# wsoc_common_secure register map
Vendor: Texas Instruments
Peripheral module from a debugger description file (folder CC35X1E).
Registers are 32-bit, access per field, reset 0x0 unless marked. A register's access mark holds for its fields unless they carry their own. Offsets are as the file gives them; lines under a group give offsets from that group; [hi:lo] are bit positions; {n}, {i} and the like mark numbered series; 'fields as' and 'values as' point back to an identical list; <NAME> marks a mode.

## wsoc_common_secure
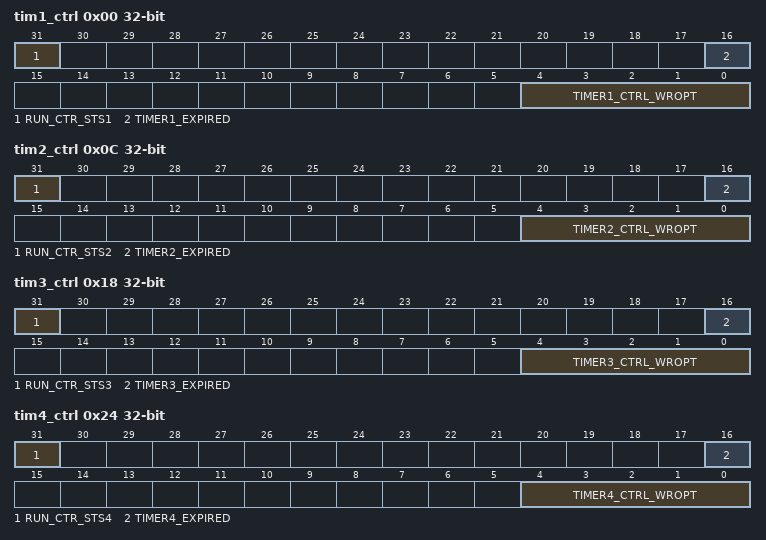
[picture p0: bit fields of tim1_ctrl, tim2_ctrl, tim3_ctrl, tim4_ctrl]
0x00 tim1_ctrl reset not defined — Control Timer Register1 (TIM1_CTRL)
  [31] RUN_CTR_STS1 ro — when value is 1, counter is running. the signal is asserted during load and count stages of the counter. if the counter is paused, this indication stays high and the pause bit should be checked as well.
  [16] TIMER1_EXPIRED ro — when set, timer has completed its count and asserted an interrupt. deasserted when started
  [4:0] TIMER1_CTRL_WROPT rw — Controls starting of timers and continuous or single shot modes; bit 3 = timer stop strobe. self-clearing. If timer running. setting bit stops the timer. A subsequent start will start the timer from load value; bit 2 = pause timer if set. Timer will stop counting down until cleared.; bit 1 = indicates continuous timer if set. single event if cleared; bit 0 = timer start. self-clearing;If stopped. setting bit 0 starts the timer. If running. setting bit 0 is ignores. bit 4 = when set, counter counts on clock freq (40MHz). when cleared, couter counts at usec frequency
0x04 tim1_load rw — Load Timer Register1 (TIM1_LOAD)
  [31:0] MEM_TIMER1_LOAD — Initial value for the timer to start counting
0x08 tim1_cnt ro — Value Timer Register1(TIM1_CNT)
  [31:0] TIMER1_COUNT — Represents the current value of the timer.
0x0C tim2_ctrl reset not defined — Control Timer Register2 (TIM2_CTRL)
  [31] RUN_CTR_STS2 ro — when value is 1, counter is running. the signal is asserted during load and count stages of the counter. if the counter is paused, this indication stays high and the pause bit should be checked as well.
  [16] TIMER2_EXPIRED ro — when set, timer has completed its count and asserted an interrupt. deasserted when started
  [4:0] TIMER2_CTRL_WROPT rw — Controls starting of timers and continuous or single shot modes; bit 3 = timer stop strobe. self-clearing. If timer running. setting bit stops the timer. A subsequent start will start the timer from load value; bit 2 = pause timer if set. Timer will stop counting down until cleared.; bit 1 = indicates continuous timer if set. single event if cleared; bit 0 = timer start. self-clearing;If stopped. setting bit 0 starts the timer. If running. setting bit 0 nored. bit 4 = when set, counter counts on clock freq (40MHz). when cleared, couter counts at usec frequency
0x10 tim2_load rw reset not defined — Load Timer Register2(TIM2_LOAD)
  [31:0] MEM_TIMER2_LOAD — Initial value for the timer to start counting
0x14 tim2_cnt ro — Value Timer Register2 (TIM2_CNT)
  [31:0] TIMER2_COUNT — Represents the current value of the timer.
0x18 tim3_ctrl — Control Timer Register3 (TIM3_CTRL)
  [31] RUN_CTR_STS3 ro — when value is 1, counter is running. the signal is asserted during load and count stages of the counter. if the counter is paused, this indication stays high and the pause bit should be checked as well.
  [16] TIMER3_EXPIRED ro — when set, timer has completed its count and asserted an interrupt. deasserted when started
  [4:0] TIMER3_CTRL_WROPT rw — Controls starting of timers and continuous or single shot modes; bit 3 = timer stop strobe. self-clearing. If timer running. setting bit stops the timer. A subsequent start will start the timer from load value; bit 2 = pause timer if set. Timer will stop counting down until cleared.; bit 1 = indicates continuous timer if set. single event if cleared; bit 0 = timer start. self-clearing;If stopped. setting bit 0 starts the timer. If running. setting bit 0 stops the timer. bit 4 = when set, counter counts on clock freq (40MHz). when cleared, couter counts at usec frequency
0x1C tim3_load rw — Load Timer Register3 (TIM3_LOAD)
  [31:0] MEM_TIMER3_LOAD — Initial value for the timer to start counting.min val is 5. actual count is 3-4 less then value
0x20 tim3_cnt ro — Value Timer Register3 (TIM3_CNT)
  [31:0] TIMER3_COUNT — Represents the current value of the timer.
0x24 tim4_ctrl — Control Timer Register4 (TIM4_CTRL)
  [31] RUN_CTR_STS4 ro — when value is 1, counter is running. the signal is asserted during load and count stages of the counter. if the counter is paused, this indication stays high and the pause bit should be checked as well.
  [16] TIMER4_EXPIRED ro — when set, timer has completed its count and asserted an interrupt. deasserted when started
  [4:0] TIMER4_CTRL_WROPT rw — Controls starting of timers and continuous or single shot modes; bit 3 = timer stop strobe. self-clearing. If timer running. setting bit stops the timer. A subsequent start will start the timer from load value; bit 2 = pause timer if set. Timer will stop counting down until cleared.; bit 1 = indicates continuous timer if set. single event if cleared; bit 0 = timer start. self-clearing;If stopped. setting bit 0 starts the timer. If running. setting bit 0 stops the timer. bit 4 = when set, counter counts on clock freq (40MHz). when cleared, couter counts at usec frequency
0x28 tim4_load rw — Load Timer Register4 (TIM4_LOAD)
  [31:0] MEM_TIMER4_LOAD — Initial value for the timer to start counting.min val is 5. actual count is 3-4 less then value
0x2C tim4_cnt ro — Value Timer Register4 (TIM4_CNT)
  [31:0] TIMER4_COUNT — Represents the current value of the timer.
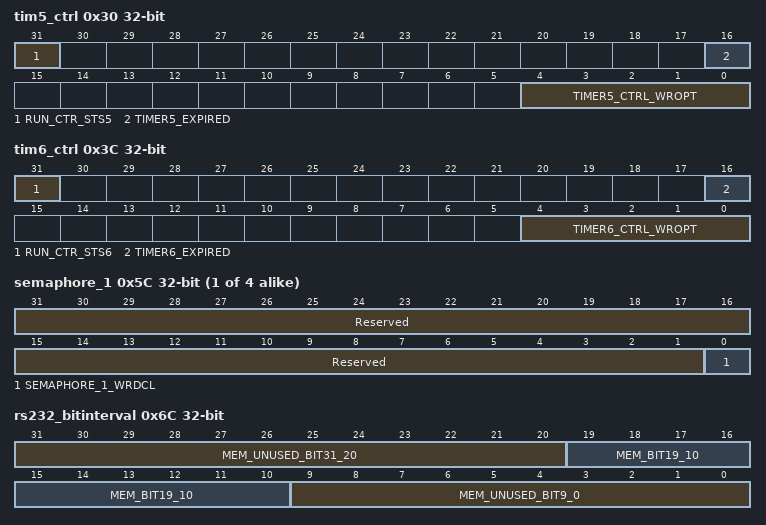
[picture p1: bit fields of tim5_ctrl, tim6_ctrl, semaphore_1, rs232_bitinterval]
0x30 tim5_ctrl — Control Timer Register5 (TIM5_CTRL)
  [31] RUN_CTR_STS5 ro — when value is 1, counter is running. the signal is asserted during load and count stages of the counter. if the counter is paused, this indication stays high and the pause bit should be checked as well.
  [16] TIMER5_EXPIRED ro — when set, timer has completed its count and asserted an interrupt. deasserted when started
  [4:0] TIMER5_CTRL_WROPT rw — Controls starting of timers and continuous or single shot modes; bit 3 = timer stop strobe. self-clearing. If timer running. setting bit stops the timer. A subsequent start will start the timer from load value; bit 2 = pause timer if set. Timer will stop counting down until cleared.; bit 1 = indicates continuous timer if set. single event if cleared; bit 0 = timer start. self-clearing;If stopped. setting bit 0 starts the timer. If running. setting bit 0 stops the timer. bit 4 = when set, counter counts on clock freq (40MHz). when cleared, couter counts at usec frequency
0x34 tim5_cnt ro — Value Timer Register5 (TIM5_CNT)
  [31:0] TIMER5_COUNT — Represents the current value of the timer.
0x38 tim5_load rw — Load Timer Register5 (TIM5_LOAD)
  [31:0] MEM_TIMER5_LOAD — Initial value for the timer to start counting. min val is 5. actual count is 3-4 less then value
0x3C tim6_ctrl — Control Timer Register6 (TIM6_CTRL)
  [31] RUN_CTR_STS6 ro — when value is 1, counter is running. the signal is asserted during load and count stages of the counter. if the counter is paused, this indication stays high and the pause bit should be checked as well.
  [16] TIMER6_EXPIRED ro — when set, timer has completed its count and asserted an interrupt. deasserted when started
  [4:0] TIMER6_CTRL_WROPT rw — Controls starting of timers and continuous or single shot modes; bit 3 = timer stop strobe. self-clearing. If timer running. setting bit stops the timer. A subsequent start will start the timer from load value; bit 2 = pause timer if set. Timer will stop counting down until cleared.; bit 1 = indicates continuous timer if set. single event if cleared; bit 0 = timer start. self-clearing;If stopped. setting bit 0 starts the timer. If running. setting bit 0 stops the timer. bit 4 = when set, counter counts on clock freq (40MHz). when cleared, couter counts at usec frequency
0x40 tim6_cnt ro — Value Timer Register6 (TIM6_CNT)
  [31:0] TIMER6_COUNT — Represents the current value of the timer.
0x44 tim6_load rw — Load Timer Register6 (TIM6_LOAD)
  [31:0] MEM_TIMER6_LOAD — Initial value for the timer to start counting. min val is 5. actual count is 3-4 less then value
0x48 wsoc_base_addresses reset not defined — base addresses for packet RAM. this is used by different modules. does not influence the OCP decoding itself
  [2:0] MEM_PRAM_BASE_ADDR rw — 3 msb (bits 23:21) of the PRAM base address
0x4C secga_skt_jump_tbl_base reset not defined
  [23:2] MEM_SKT_JUMP_TBL_ADDR rw — Nab Soket Jump table address. Each Table entry contain a 4B pointer to related socket DB entry. the value of this register is locked upon MEM_HIF_STATUS_LOCK @Init. In BSD_BYPASS Mode, when nab serves SDIO, only socket 0 DB exists in table. the rest 124B were increased to 124W are used to hold the Tx info table that is returned to the SDIO host at the end of each rcv() request. In the BSD_BYPASS Mode there is a restriction on value that can be set: MUST BE 128W aligned! since 2 lsb's are always 0 it means that MMR Fiels 7 LSBs MEM_SKT_JUMP_TBL_ADDR[6:0] should be set as 0
0x50 lnk_jump_tbl_base reset not defined
  [23:2] MEM_LNK_JUMP_TBL_ADDR rw
0x54 role_jump_tbl_base reset not defined
  [23:2] MEM_ROLE_JUMP_TBL_ADDR rw
0x58 secga_sub_desc_ram_base reset not defined
  [23:2] MEM_SUD_RAM_STS2_ADDR rw — Nab Sub descriptor RAM Base address. the value of this register is locked upon MEM_HIF_STATUS_LOCK @Init. In BSD_BYPASS Mode, when nab doesn't use the sud RAM, this register contains an MMR address. This MMR, plus pre-defined number of successive MMR's, return to the SDIO host as status information (a.k.a. Status 2) at the end of each rcv() request. In the BSD_BYPASS Mode there is a restriction on value that can be set: MUST BE 16W aligned! since 2 lsb's are always 0 it means that MMR Fiels 4 LSBs MEM_SUD_RAM_STS2_ADDR[3:0] should be set as 0
{0x58+4i} semaphore_{i} (i=1..4)
  [31:1] Reserved ro — rserved
  [0] SEMAPHORE_{i}_WRDCL rw — Set by read, cleared by write
0x6C rs232_bitinterval rw reset not defined — RS232 Bit Interval (RS232_BITINTERVAL) Register
  [31:20] MEM_UNUSED_BIT31_20
  [19:10] MEM_BIT19_10 — Bit Interval Value for sampling RS232 serial Data when the MAC Subsystem is working at 40 Mhz
  [9:0] MEM_UNUSED_BIT9_0
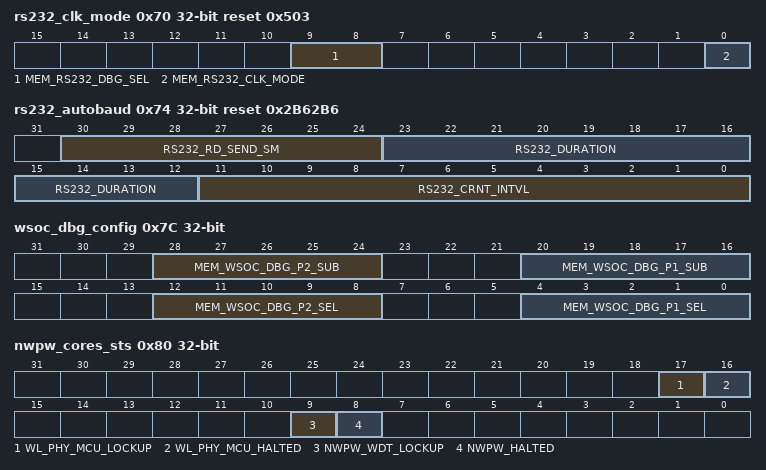
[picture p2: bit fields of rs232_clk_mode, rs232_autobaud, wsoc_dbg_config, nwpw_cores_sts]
0x70 rs232_clk_mode reset 0x503 — RS232 Clock Mode (RS232_CLK_MODE) Register
  [9:8] MEM_RS232_DBG_SEL rw — debug port select. 0 - default 0 1 - ocp debug port 2 - FSM debug port
  [0] MEM_RS232_CLK_MODE rw — RS232 Auto baud selection;0: RS232 calculates bit interval automatically based on the sleep clock frequency.;1: RS232 uses bit interval programmed by eCPU
0x74 rs232_autobaud ro reset 0x2B62B6 (reset mask 0xFFFFFF) — RS232 Auto Baud (RS232_AUTOBAUD) Register
  [30:24] RS232_RD_SEND_SM
  [23:12] RS232_DURATION — Number of ocp clocks measured in one sleep clock frequency
  [11:0] RS232_CRNT_INTVL — Current RS232 bit interval being used.
0x78 rs232_16_bit_slv — RS232 SLAVE Configuration
  [0] MEM_RS232_16_BIT_SLAVE rw — 0 = rs232 access 32 bit data slave 1 = rs232 access 16 bit data slave
0x7C wsoc_dbg_config — WSOC OCLA Debug Port Config register
  [28:24] MEM_WSOC_DBG_P2_SUB rw — Test Port Select (sub module = coulmn in XSL)
  [20:16] MEM_WSOC_DBG_P1_SUB rw — Test Port Select (sub module = coulmn in XSL)
  [12:8] MEM_WSOC_DBG_P2_SEL rw — Test Port module Select (up to 8 modules. bit 4 serves as test port selection)
  [4:0] MEM_WSOC_DBG_P1_SEL rw — Test Port module Select (up to 8 modules. bit 4 serves as test port selection)
0x80 nwpw_cores_sts ro
  [17] WL_PHY_MCU_LOCKUP — wl_phy_mcu lockup status
  [16] WL_PHY_MCU_HALTED — wl_phy_mcu halt status
  [9] NWPW_WDT_LOCKUP — wsoc_mcu lockup status
  [8] NWPW_HALTED — wsoc_mcu halt status
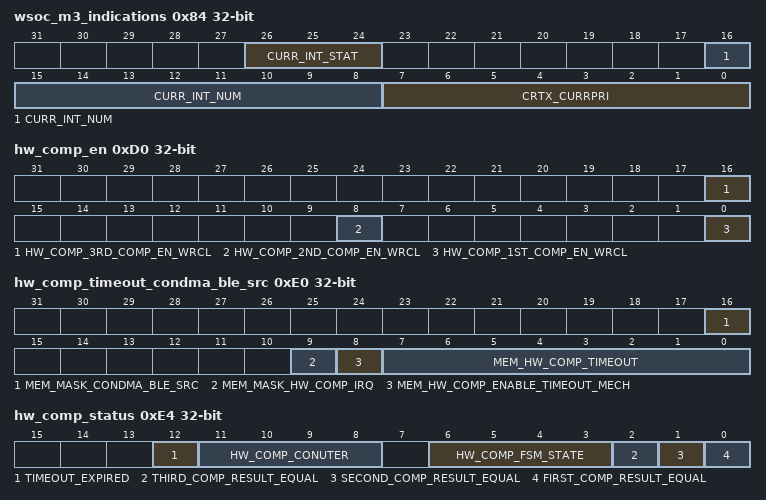
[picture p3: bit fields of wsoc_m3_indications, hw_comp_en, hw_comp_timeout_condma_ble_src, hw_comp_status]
0x84 wsoc_m3_indications ro
  [26:24] CURR_INT_STAT — Interrupt activation status
  [16:8] CURR_INT_NUM — Interrupt that is currently active
  [7:0] CRTX_CURRPRI — Current Int Priority index
0x88 fpga_version ro
0x8C wsoc_err_mask
  [15:0] MEM_WSOC_ERR_MASK rw — when set, the corresponding err source will not trigger an interrupt to SW and will not be visible in WSOC_ERR_STS_MASKED.
0x90 wsoc_err_sts_raw — source list: [0] = mmu_error_irq [1] = wsoc_mcu_addr_error_irq [2] = descr_fifo_error_irq [3] = wsoc_wmac_err_irq [4] = mmu_addr_trans_err_irq [5] = enc_abort_at_tx_error_irq [6] = enc_wr_cmd_error_irq [7] = ocp_ic_serror_irq [8] = ocp_ic_timeout_irq [9] = ocp_ic_addr_watch_irq [10] = soc_ic_serror_irq [11] = soc_ic_timeout_irq [12] = soc_ic_addr_watch_irq [13] = pll_unlock_irq [14] = phy_ocp_ic_serror_irq [15] = phy_ocp_ic_timeout_irq
  [15:0] WSOC_ERR_STS_WROPT rw — each bit indicate if the error source was triggered. writing '1' to each separate bith will clear it. writing '0' to a bit does not have any influence
0x94 wsoc_err_sts_masked
  [15:0] WSOC_ERR_STS_MASKED_WROPT rw — each bit indicate if the error was triggered, subject to the mask defined in WSOC_ERR_MASK. writing '1' to each separate bith will clear it. writing '0' to a bit does not have any influence
0x98 gpio_in_1 ro — GPIO Input Values (GPIO_IN_1) Register
  [31:0] GPIO_IN_0_TO_31 — GPIO Input Values. gpio 0 to 31
0x9C gpio_in_2 ro — GPIO Input Values (GPIO_IN_1) Register
  [12:0] GPIO_IN_32_to_44 — GPIO Input Values. gpio 32 to 45
0xA8 spare_a1 — Spare registers (SPARE_A1)
  [0] MEM_SPARE_A1 rw — Spare register
0xAC spare_a2 — Spare registers (SPARE_A2)
  [0] MEM_SPARE_A2 rw — Spare register
0xB0 spare_a3 — Spare registers (SPARE_A3)
  [1:0] MEM_SPARE_A3 rw — Spare register
0xB4 spare_a4 — Spare registers (SPARE_A4)
  [1:0] MEM_SPARE_A4 rw — Spare register
0xB8 spare_a5 — Spare registers (SPARE_A5)
  [3:0] MEM_SPARE_A5 rw — Spare register
0xBC spare_a6 — Spare registers (SPARE_A6) in functional mode, bit 0 read value is the rx_complete_t_ff signal indicating which packet does the double buffer currently points to.
  [7:0] MEM_SPARE_A6 rw — Spare register
0xC0 spare_a7 access not given — Spare registers (SPARE_A7)
  [15:0] MEM_SPARE_A7 — Spare register
0xC4 spare_a8 rw — Spare
  [31:0] MEM_SPARE_A8 — Spare register
0xC8 hw_comp_clr — HW_COMP_CLR clear the a and b operands
  [0] HW_COMP_CLR_WRCL wo
0xCC hw_comp_clr_result — clears the exisiting results
  [0] HW_COMP_CLR_RESULT_WRCL wo
0xD0 hw_comp_en — bit0 - enable 1st comp bit8 - enable 2nd comp bit16 - enable 3rd comp
  [16] HW_COMP_3RD_COMP_EN_WRCL wo — 3rd mechanism enable - magic word
  [8] HW_COMP_2ND_COMP_EN_WRCL wo — 2n mechaism en- IRQ equal and not equal
  [0] HW_COMP_1ST_COMP_EN_WRCL wo — first mechanism - status only
0xD4 hw_comp_operand_a wo — HW comperator operand a 32 bit width
  [31:0] HWCOMP_OPERAND_A_WROPT
0xD8 hw_comp_operand_b wo — HW comperator operand b 32 bit width
  [31:0] HWCOMP_OPERAND_B_AND_COMPARE_WROPT
0xDC hw_comp_magic_num
  [7:0] HW_COMP_MAGIC_NUMBER_WROPT rw
0xE0 hw_comp_timeout_condma_ble_src
  [16] MEM_MASK_CONDMA_BLE_SRC rw — choose condma ch 2,3 source 0: SDIO 1:UART
  [9] MEM_MASK_HW_COMP_IRQ rw — time out conuter in 16 usec resolution
  [8] MEM_HW_COMP_ENABLE_TIMEOUT_MECH rw — enable timeout mechanism on hw comp
  [7:0] MEM_HW_COMP_TIMEOUT rw — time out conuter in 16 usec resolution
0xE4 hw_comp_status ro — assign hw_comp_status = {2'h0,timeout_expired,hw_comp_conuter,1'h0,hw_comp_fsm_state,third_comp_result_equal,second_comp_result_equal,first_comp_result_equal};
  [12] TIMEOUT_EXPIRED — is the timeout expired between reads when mechasims are enabled
  [11:8] HW_COMP_CONUTER — current operand portion counter - 0 to 7. the measure is done only when it is 7 because we need to compare 256 perands.
  [6:3] HW_COMP_FSM_STATE — localparam [3:0] // synopsys enum state_info IDLE = 4'h0, COMP1 = 4'h1, COMP1_DONE = 4'h2, COMP1_FAIL = 4'h3, COMP2 = 4'h4, COMP2_DONE = 4'h5, COMP2_FAIL = 4'h6, COMP3 = 4'h7, COMP3_FAIL = 4'h8, DONE = 4'h9, EXPIRY = 4'ha;
  [2] THIRD_COMP_RESULT_EQUAL — current operand portion counter - 0 to 7. the measure is done only when it is 7 because we need to compare 256 perands.
  [1] SECOND_COMP_RESULT_EQUAL — current operand portion counter - 0 to 7. the measure is done only when it is 7 because we need to compare 256 perands.
  [0] FIRST_COMP_RESULT_EQUAL — current operand portion counter - 0 to 7. the measure is done only when it is 7 because we need to compare 256 perands.
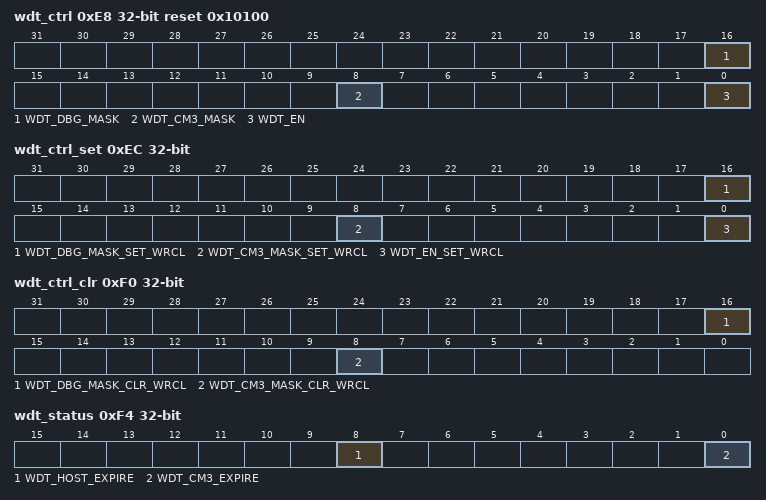
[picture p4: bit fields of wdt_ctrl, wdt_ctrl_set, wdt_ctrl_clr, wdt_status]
0xE8 wdt_ctrl ro reset 0x10100
  [16] WDT_DBG_MASK — If DBGEN = 0 (CM3 not being debugged), this has no effect. If DBGEN = 1, this bit masks watchdog IRQs (both Thresholds) to the system. Set 1 - Mask IRQ (i.e. Disable). Set 0 - Unmaske IRQ (i.e. Enable).
  [8] WDT_CM3_MASK — Mask WDT IRQ triggered by reaching CM3 Threshold. Set 1 - Mask IRQ (i.e. Disable). Set 0 - Unmaske IRQ (i.e. Enable).
  [0] WDT_EN — WDT Enable Value. Disabled by default. Can be set by SW (only once).
0xEC wdt_ctrl_set
  [16] WDT_DBG_MASK_SET_WRCL wo, [8] WDT_CM3_MASK_SET_WRCL wo, [0] WDT_EN_SET_WRCL wo
0xF0 wdt_ctrl_clr
  [16] WDT_DBG_MASK_CLR_WRCL wo, [8] WDT_CM3_MASK_CLR_WRCL wo
0xF4 wdt_status ro
  [8] WDT_HOST_EXPIRE — if WDT Host Threshold (#2) is reached (WDT is expired), this bit is set to 1.
  [0] WDT_CM3_EXPIRE — if WDT CM3 Threshold (#1) is reached, This bit is set to 1.
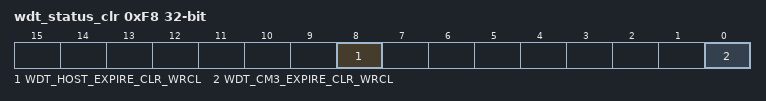
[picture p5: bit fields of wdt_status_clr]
0xF8 wdt_status_clr
  [8] WDT_HOST_EXPIRE_CLR_WRCL wo, [0] WDT_CM3_EXPIRE_CLR_WRCL wo
0xFC wdt_cnt ro
  [25:0] WDT_CNT_VAL — WDT Counter Value.
0x100 wdt_cnt_clr
  [0] WDT_CLR_TO_0_WRCL wo — Reset WDT Counter to 0 (WDT will still be enabled).
0x104 wdt_cm3_thresh
  [25:10] MEM_WDT_CM3_TH_VAL rw — When WDT is triggerd it counts up till reaching this value. WDT IRQ is triggered when reaching this value. 10 lsb are 0 and are ignored when written to. this gives a resolution of 2^10 which is 1.024 msec.
0x108 wdt_host_thresh
  [25:10] MEM_WDT_HOST_TH_VAL rw — When WDT is triggerd it counts up till reaching this value. WDT IRQ is triggered when reaching this value. 10 lsb are 0 and are ignored when written to. this gives a resolution of 2^10 which is 1.024 msec.
0x10C wifi_ant_ctrl reset not defined — This register controls the Wifi ant selecetion to ant control logic . Wif core antenna request
  [1:0] MEM_COEX_ANT_CTRL_WIFI rw — 3 msb (bits 23:21) of the PRAM base address
0x110 secga_hif_status_lock reset not defined — Lock command to HIF status base adderess
  [0] MEM_HIF_STATUS_LOCK rw — Write this bit to lock status 1 and 2 of SDIO/WSPI WSOC bridge. this lock is getting reset every LPDS and needs to be written again. Following regs are locked by this reg: 1. MEM_SKT_JUMP_TBL_ADDR 2. MEM_SUD_RAM_STS2_ADDR
